# IND83215A register map
Series: Verne; File version: A0
CPU: CM0 r0p1, selectable endian, no MPU, no FPU, 4 interrupt priority bits
Registers are 32-bit, read-write, no defined reset value unless marked. A register's access mark holds for its fields unless they carry their own. Offsets are from the block's base; [hi:lo] are bit positions; {n}, {i} and the like mark numbered series; <NAME> marks a mode.

## EVTHOLD — Event Hold Control
Base 0x50013000; register names take the prefix EVTHOLD_
0x00 HOLD
  [0] HOLD wo — Hold. Set to prevent serialisation of new non-wakeup events in prepartion for hibernate mode. At the point of becoming set, a request to send the lullaby interrupt is automatically generated. The lullaby handler can then safely assert the PMUA->CTRL.HIBERNATE bit in order to put the device into hibernate mode.

## SYSCFG — System Configuration Located in Power Down Domain.
Base 0x50020000; register names take the prefix SYSCFG_
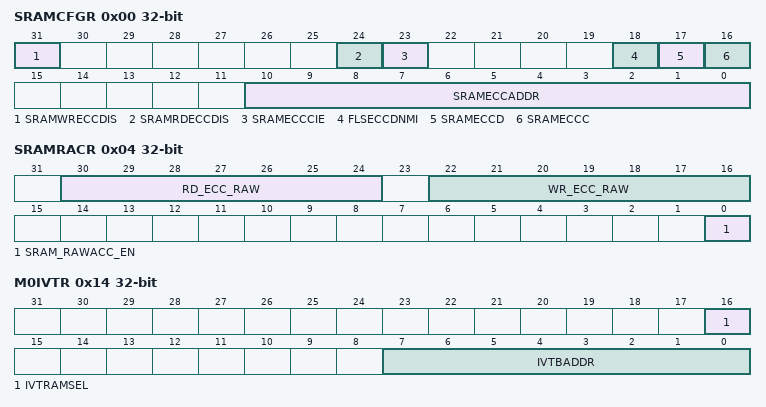
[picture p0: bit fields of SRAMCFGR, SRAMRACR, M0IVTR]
0x00 SRAMCFGR — SRAM Configuration Register.
  [31] SRAMWRECCDIS — SRAM WRITE ECC Disable bit. 0x0: SRAM WRITE ECC function enabled 0x1: SRAM WRITE ECC function disabled
  [24] SRAMRDECCDIS — SRAM READ ECC Disable bit. 0x0: SRAM READ ECC function enabled 0x1: SRAM READ ECC function disabled
  [23] SRAMECCCIE — SRAM ECC correction interrupt enable. 0x0: SRAMECCC interrupt disabled 0x1: SRAMECCC interrupt enabled
  [18] FLSECCDNMI ro — Flash ECC detection Indication. This bit reflect status of ECCD bit of register FLSECCR.
  [17] SRAMECCD dual — SRAM ECC detection. Set by hardware when two bits ECC errors has been detected and corrected when access SRAM. When this bit is set, a NMI is generated. Cleared by writing 1.
  [16] SRAMECCC dual — SRAM ECC correction. Set by hardware when one bit ECC error has been detected and corrected when access sram. An interrupt is generated if SRAMECCIE is set. Cleared by writing 1.
  [10:0] SRAMECCADDR ro — SRAM ECC Error Address.
0x04 SRAMRACR — SRAM Raw Access Control Register.
  [30:24] RD_ECC_RAW ro — ECC Raw Value for Read. This field store the data from SRAM bit[38:32] when SRAM_RAWACC_EN is set.
  [22:16] WR_ECC_RAW — ECC Raw Value for Write. This field will write to SRAM when bit[31:24] is writing and SRAM_RAWACC_EN is set.
  [0] SRAM_RAWACC_EN — SRAM Raw Access Enable. Set to enable raw access to SRAM. NOTE: SRAM_ECC_DIS need to set when executing raw access.
0x08 SRAMWPKEYR — SRAM Write Protection Register key register.
  [7:0] SRAMWPKEY — Write pretection key for SRAMWPR to take effect. A value of 0x26 must be written to this address to allow SRAMWPR to take effect.
0x0C SRAMWPR — SRAM Write Protection Register.
  [15:0] SRAMWP — SRAM Write Protection. Each bit protect 1Kbyte SRAM area, bit0 correspondint the first 1Kbyte. This field is set only. 0x0: Corresponding 1K area can be modified 0x1: Corresponding 1K area write protected
0x10 M0IVTRKEYR — M0 Interrupt Vector Table write key register.
  [7:0] M0IVTRKEY — Write pretection key for M0IVTR to take effect. A value of 0x53 must be written to this address to allow M0IVTR to take effect.
0x14 M0IVTR — M0 Interrupt Vector Table Register.
  [16] IVTRAMSEL — IVT SRAM Selection. 0x0: IVT is located in Flash 0x1: IVT is located in SRAM
  [7:0] IVTBADDR — Interrupt Vector Table Base Address. This field contains the base address of the interrupt vector table remapping block. IVT_BADDR will be used to replace Address[15:8] if Address[31:8] is equal to 0x0 (Access first 256 byte space). When IVTRAMSEL=0, remapped address will be {Address[31:16],IVTBADDR,Address[7:0]}; When IVTRAMSEL=1, remapped address will be {16'h2000,IVTBADDR,Address[7:0]}.

## TIMER0 — General purpose timer 0 registers
Base 0x50022000; register names take the prefix TIMER0_
0x00 COUNT — Timer Counter Register.
  [31:0] COUNT — Count. Initial counter value. The timer will count from this value to 0xFFFFFFFF and roll over to 0x00000000. At this point it will generate an interrupt if enabled. The interrupt routine is responsible for reloading the value if needed as this timer does not auto-reload the original content.
0x04 CFG — Timer Control Register.
  [0] ENA — Enable. This bit starts/stops the timer: < br> 1 = Timer Running < br> 0 = Timer Inactive

## TIMER1 — General purpose timer 1 registers
Base 0x50022008; register names take the prefix TIMER1_
Registers as TIMER0.

## TIMER2 — General purpose timer 2 registers
Base 0x50022010; register names take the prefix TIMER2_
Registers as TIMER0.

## WDT1 — The watchdog timer that is local to VERNE MCU
Base 0x50022018; register names take the prefix WDT1_
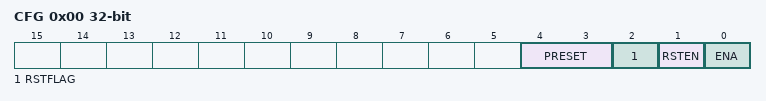
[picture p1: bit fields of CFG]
0x00 CFG — Config.
  [4:3] PRESET — Preset. Defines the watchdog timeout period. It means that the WDT internal counter will count from 0 to the prescaler value at the system clock speed and trigger if not cleared. For instance, a system running from a 30MHz Crystal with WDTPRES[1I0] = 10 will trigger the WDT after approximately 0.14 seconds if not cleared properly and in time by the application. 0x0: 2^13 / System Clock 0x1: 2^19 / System Clock 0x2: 2^22 / System Clock 0x3: 2^32 / System Clock
  [2] RSTFLAG — Reset flag. This flag is set by the system at the initialization if the initialization was caused by a reset triggered by the WDT. The bit can be cleared by the application.
  [1] RSTEN — Reset enable. If enabled a WDT time-out will force the microcontroller to reset. This bit can be asserted but it cannot be de-asserted.
  [0] ENA — WDT Enable. This bit can be asserted but it cannot be de-asserted. It means that once the WDT is enabled it cannot be turned off until a Reset or Power-On Reset occurs.
0x04 KEY — Key. Writing the sequence CLEAR, KEY0, KEY1 to this register will clear (pet) the watchdog - preventing it from timing out and resetting the system.
  [31:0] KEY — Key. To clear the WDT counting the following words must be written in this order and without any other instruction between then: 0x3C570001 0x007F4AD6

## CRC — CRC32 Registers.
Base 0x50022100; register names take the prefix CRC_
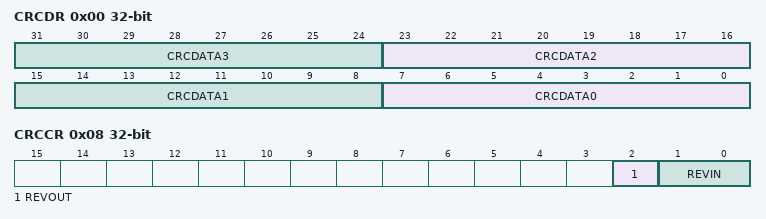
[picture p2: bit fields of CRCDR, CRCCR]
0x00 CRCDR — CRC Data Register
  [8n+7:8n] CRCDATA{n} dual (n=0..3) — CRC data bits. This register is used to write new data to the CRC calculator. When read it returns the previous CRC calculation result or the data write to CRCINIT If the data size is less than 32 bits, only the least significant bits will be take effect. ex. byte write to field [15:8] will be ignored, half-word write to bit field [31:16] will be ignored
0x04 CRCIR — CRC Initial Value Register
  [31:0] CRCINIT wo — CRC initial value. This register is used to write the CRC initial value. The data write to this register will be stored in CRCDATA until it replaced by new calculated result NOTE: This register can only be writen by word
0x08 CRCCR — CRC Control Register
  [2] REVOUT — Reverse output data. This bit controls the reversal of the bit order of the output data. 0x0: Bit order not affected 0x1: Bit order is reversed
  [1:0] REVIN — Reverse input data. These bits control the reversal of the bit order of the input data 0x0: Bit order not affected 0x1: Bit reversal done by byte 0x2: Bit reversal done by half-word 0x3: Bit reversal done by word
